# CONTROLSS_GLOBAL_CTRL_CONTROLSS_CTRL_502F0000h register map
Vendor: Texas Instruments
Peripheral module from a debugger description file (folder AM263P).
Registers are 32-bit, read-write, reset 0x0 unless marked. A register's access mark holds for its fields unless they carry their own. Offsets are as the file gives them; lines under a group give offsets from that group; [hi:lo] are bit positions; {n}, {i} and the like mark numbered series; 'fields as' and 'values as' point back to an identical list; <NAME> marks a mode.

## CONTROLSS_CTRL
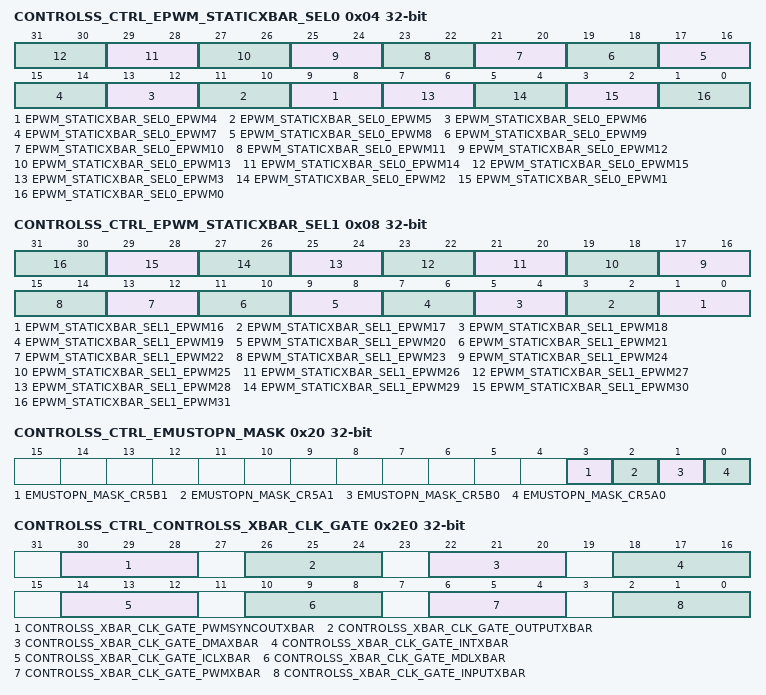
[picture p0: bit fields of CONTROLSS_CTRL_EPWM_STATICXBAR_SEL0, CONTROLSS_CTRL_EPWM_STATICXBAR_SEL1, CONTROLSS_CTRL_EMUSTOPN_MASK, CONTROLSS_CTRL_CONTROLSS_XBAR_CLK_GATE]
0x04 CONTROLSS_CTRL_EPWM_STATICXBAR_SEL0 — Static crossbar for epwm select.
  [2n+1:2n] EPWM_STATICXBAR_SEL0_EPWM{n} (n=4..15) — EPWM{n} access from PCR grouping. Write the following value to access groups - - 2'b00 = G0, 2'b01 =G1, 2'b10 =G2, 2'b11 =G3
  [7:6] EPWM_STATICXBAR_SEL0_EPWM3 — EPWM3 access from PCR grouping. Write the following value to access groups - 2'b00 = G0, 2'b01 =G1, 2'b10 =G2, 2'b11 =G3
  [5:4] EPWM_STATICXBAR_SEL0_EPWM2 — EPWM2 access from PCR grouping. Write the following value to access groups - - 2'b00 = G0, 2'b01 =G1, 2'b10 =G2, 2'b11 =G3
  [3:2] EPWM_STATICXBAR_SEL0_EPWM1 — EPWM1 access from PCR grouping. Write the following value to access groups - - 2'b00 = G0, 2'b01 =G1, 2'b10 =G2, 2'b11 =G3
  [1:0] EPWM_STATICXBAR_SEL0_EPWM0 — EPWM0 access from PCR grouping. Write the following value to access groups - - 2'b00 = G0, 2'b01 =G1, 2'b10 =G2, 2'b11 =G3
0x08 CONTROLSS_CTRL_EPWM_STATICXBAR_SEL1 — Static crossbar for epwm select.
  [2n-31:2n-32] EPWM_STATICXBAR_SEL1_EPWM{n} (n=16..31) — EPWM{n} access from PCR grouping. Write the following value to access groups - - 2'b00 = G0, 2'b01 =G1, 2'b10 =G2, 2'b11 =G3
0x10 CONTROLSS_CTRL_EPWM_CLKSYNC — Epwm clock sync.
  [31:0] EPWM_CLKSYNC_BIT — EPWM clock sync for each EPWM instance. Set the bit corresponding to the instance number to enable that EPWM instance. When set, all enabled EPWM module clocks are started with the first rising edge of TBCLK aligned.Refer to TRM for more details.Writing 1'b1 will allow to enable corresponding EPWM instanceWriting 1'b0 will disable corresponding EPWM instance.
0x18 CONTROLSS_CTRL_SDFM1_CLK0_SEL — Sdfm1 clock select.
  [0] SDFM1_CLK0_SEL_SEL — SDFM1 clock CK0 selectWrite 1'b0: source is SDFM1 CK0 from PinmuxWrite 1'b1: source is SDFM0 CK0 from Pinmux
0x20 CONTROLSS_CTRL_EMUSTOPN_MASK — Bit-mask for debug suspend cpu cores to EPWM.
  [3] EMUSTOPN_MASK_CR5B1 — Bit-mask for debug suspend cpu cores to EPWM1'b0 : R5FSS1_CORE1 enabled to control EMUSTOPn1'b1 : R5FSS1_CORE1 disabled to control EMUSTOPn
  [2] EMUSTOPN_MASK_CR5A1 — Bit-mask for debug suspend cpu cores to EPWM1'b0 : R5FSS1_CORE0 enabled to control EMUSTOPn1'b1 : R5FSS1_CORE0 disabled to control EMUSTOPn
  [1] EMUSTOPN_MASK_CR5B0 — Bit-mask for debug suspend cpu cores to EPWM1'b0 : R5FSS0_CORE1 enabled to control EMUSTOPn1'b1 : R5FSS0_CORE1 disabled to control EMUSTOPn
  [0] EMUSTOPN_MASK_CR5A0 — Bit-mask for debug suspend cpu cores to EPWM1'b0 : R5FSS0_CORE0 enabled to control EMUSTOPn1'b1 : R5FSS0_CORE0 disabled to control EMUSTOPn
0x28 CONTROLSS_CTRL_CLB_AQ_EN0 — clb_aq_en0.
  [31:0] CLB_AQ_EN0_ENABLE — Enable ICCS control to CLB_AQ signal of PWM[15:0]. Set Bitx to 1'b1 to enable it for PWMx. Here x varies from 0-15.
0x30 CONTROLSS_CTRL_CLB_AQ_EN1 — clb_aq_en1.
  [31:0] CLB_AQ_EN1_ENABLE — Enable ICCS control to CLB_AQ signal of PWM[31:16].Set Bitx to 1'b1 to enable it for PWMx. Here x varies from 16-31.
0x38 CONTROLSS_CTRL_CLB_DB_EN0 — clb_db_en0.
  [31:0] CLB_DB_EN0_ENABLE — Enable ICCS control to CLB_DB signal of PWM[15:0]. Set Bitx to 1'b1 to enable it for PWMx. Here x varies from 0-15.
0x40 CONTROLSS_CTRL_CLB_DB_EN1 — clb_db_en1.
  [31:0] CLB_DB_EN1_ENABLE — Enable ICCS control to CLB_DB signal of PWM[31:16].Set Bitx to 1'b1 to enable it for PWMx. Here x varies from 16-31.
0x44 CONTROLSS_CTRL_ADCSOCFRCGBSEL — ADC Global SoC Force select.
  [6:0] ADCSOCFRCGBSEL_ENABLE — ADCSOCFRCGBSEL has one bit for each ADCBIT FIELD Descriptionbitx ADCx Indicate if ADCx selected for global SW trigger 1'b0 : Not selected for Global SW Trigger 1'b1 : Selected for Global SW TriggerReset Reset type: SYSRSnNote: x represents 0-4
0x48 CONTROLSS_CTRL_ADCSOCFRCGB — ADC Global SOC Force.
  [15:0] ADCSOCFRCGB_TRIG — ADCSOCFRCGB has one bit for each SOC[Start of conversion]BIT FIELD Descriptionbitxx SOCxx Indicate if SOCxx selected for global SW trigger 1'b0 : Not selected for Global SW Trigger 1'b1 : Selected for Global SW Trigger Reset type: SYSRSnNote: xx represents 0-15
0x4C CONTROLSS_CTRL_ADC_EXTCH_DLY_SEL — Mux select to choose delay for adc_extchsel.
  [0] ADC_EXTCH_DLY_SEL_SEL — MUX select to choose delayWrite 1'b0: 3 cycle delay[default]Write 1'b1: 6 cycle delay
0x50 CONTROLSS_CTRL_XBAR_LOOPBACK_CTRL — Mux select to enable Loopback for corresponding outputXBAR.
  [15:0] XBAR_LOOPBACK_CTRL_ENABLE — Mux select to enable Loopback for corresponding outputXBAR signal to the inputXBARWrite 1'b0: Loopback disabled [default]Write 1'b1: Loopback enable**Note: Each Mux select bit corresponds to the corresponding XBAR_LOOPBACK_CTRL_MUX
0x60 CONTROLSS_CTRL_EPWM_SOCA_SEL — Select line to choose EPWM SOC A to EQEPx.SOCA and PWMBAR.
  [31:0] EPWM_SOCA_SEL_SEL — MUX select to choose EPWM SOC A to EQEPx.SOCA and PWMBAR.Each bit in SOC_A_SEL corresponds to each inputEPWM_SOCA_SEL_0:pwm_soca_0EPWM_SOCA_SEL_1:pwm_soca_1EPWM_SOCA_SEL_2:pwm_soca_2EPWM_SOCA_SEL_3:pwm_soca_3EPWM_SOCA_SEL_4:pwm_soca_4EPWM_SOCA_SEL_5:pwm_soca_5EPWM_SOCA_SEL_6:pwm_soca_6EPWM_SOCA_SEL_7:pwm_soca_7EPWM_SOCA_SEL_8:pwm_soca_8EPWM_SOCA_SEL_9:pwm_soca_9EPWM_SOCA_SEL_10:pwm_soca_10EPWM_SOCA_SEL_11:pwm_soca_11EPWM_SOCA_SEL_12:pwm_soca_12EPWM_SOCA_SEL_13:pwm_soca_13EPWM_SOCA_SEL_14:pwm_soca_14EPWM_SOCA_SEL_15:pwm_soca_15EPWM_SOCA_SEL_16:pwm_soca_16EPWM_SOCA_SEL_17:pwm_soca_17EPWM_SOCA_SEL_18:pwm_soca_18EPWM_SOCA_SEL_19:pwm_soca_19EPWM_SOCA_SEL_20:pwm_soca_20EPWM_SOCA_SEL_21:pwm_soca_21EPWM_SOCA_SEL_22:pwm_soca_22EPWM_SOCA_SEL_23:pwm_soca_23EPWM_SOCA_SEL_24:pwm_soca_24EPWM_SOCA_SEL_25:pwm_soca_25EPWM_SOCA_SEL_26:pwm_soca_26EPWM_SOCA_SEL_27:pwm_soca_27EPWM_SOCA_SEL_28:pwm_soca_28EPWM_SOCA_SEL_29:pwm_soca_29EPWM_SOCA_SEL_30:pwm_soca_30EPWM_SOCA_SEL_31:pwm_soca_31
0x64 CONTROLSS_CTRL_EPWM_SOCB_SEL — Select line to choose EPWM SOC B to EQEPx.SOCB and PWMBAR.
  [31:0] EPWM_SOCB_SEL_SEL — MUX select to choose EPWM SOC B to EQEPx.SOCB and PWMBAR.Each bit in SOC_B_SEL corresponds to each inputEPWM_SOCB_SEL_0:pwm_socb_0EPWM_SOCB_SEL_1:pwm_socb_1EPWM_SOCB_SEL_2:pwm_socb_2EPWM_SOCB_SEL_3:pwm_socb_3EPWM_SOCB_SEL_4:pwm_socb_4EPWM_SOCB_SEL_5:pwm_socb_5EPWM_SOCB_SEL_6:pwm_socb_6EPWM_SOCB_SEL_7:pwm_socb_7EPWM_SOCB_SEL_8:pwm_socb_8EPWM_SOCB_SEL_9:pwm_socb_9EPWM_SOCB_SEL_10:pwm_socb_10EPWM_SOCB_SEL_11:pwm_socb_11EPWM_SOCB_SEL_12:pwm_socb_12EPWM_SOCB_SEL_13:pwm_socb_13EPWM_SOCB_SEL_14:pwm_socb_14EPWM_SOCB_SEL_15:pwm_socb_15EPWM_SOCB_SEL_16:pwm_socb_16EPWM_SOCB_SEL_17:pwm_socb_17EPWM_SOCB_SEL_18:pwm_socb_18EPWM_SOCB_SEL_19:pwm_socb_19EPWM_SOCB_SEL_20:pwm_socb_20EPWM_SOCB_SEL_21:pwm_socb_21EPWM_SOCB_SEL_22:pwm_socb_22EPWM_SOCB_SEL_23:pwm_socb_23EPWM_SOCB_SEL_24:pwm_socb_24EPWM_SOCB_SEL_25:pwm_socb_25EPWM_SOCB_SEL_26:pwm_socb_26EPWM_SOCB_SEL_27:pwm_socb_27EPWM_SOCB_SEL_28:pwm_socb_28EPWM_SOCB_SEL_29:pwm_socb_29EPWM_SOCB_SEL_30:pwm_socb_30EPWM_SOCB_SEL_31:pwm_socb_31
{0x70+4i} CONTROLSS_CTRL_ADCEXTCHXBAR{i}_G0_SEL (i=0..9) — ADC EXTCH XBAR [x] Input Select.
  [3:0] ADCEXTCHXBAR{i}_G0_SEL_SEL — ADC EXTCH XBAR 0 Input Select4'b0000: ADC0EXTCHSEL_BIT04'b0001: ADC0EXTCHSEL_BIT14'b0010: ADC1EXTCHSEL_BIT04'b0011: ADC1EXTCHSEL_BIT14'b0100: ADC2EXTCHSEL_BIT04'b0101: ADC2EXTCHSEL_BIT14'b0110: ADC3EXTCHSEL_BIT04'b0111: ADC3EXTCHSEL_BIT14'b1000: ADC4EXTCHSEL_BIT04'b1001: ADC4EXTCHSEL_BIT14'b1010: ADC_R0_EXTCHSEL_BIT04'b1011: ADC_R0_EXTCHSEL_BIT14'b1100: ADC_R1_EXTCHSEL_BIT04'b1101: ADC_R1_EXTCHSEL_BIT1Example: ADC2EXTCHSEL_BIT0 needs to be connect to ADC_EXTCH_XBAROUT3, then ADCEXTCHXBAR3.G0.SEL set to 4'b0100
{0xB0+4i} CONTROLSS_CTRL_SDFM0_CLK{i}_OUT_SEL (i=0..3) — SDFM0_CLK[x]_OUT Input Select.
  [0] SDFM0_CLK{i}_OUT_SEL_SEL — SDFM0_CLK{i}_OUT Input selectWrite 1'b0: ECAP{i+4}_OUT [default]Write 1'b1: ECAP{i+12}_OUT
0xC0 CONTROLSS_CTRL_SDFM1_CLK0_OUT_SEL — SDFM1_CLK[x]_OUT Input Select.
  [0] SDFM1_CLK0_OUT_SEL_SEL — SDFM1_CLK0_OUT Input selectWrite 1'b0: ECAP7_OUT [default]Write 1'b1: ECAP15_OUT
0xC4 CONTROLSS_CTRL_SDFM1_CLK1_OUT_SEL — SDFM1_CLK[x]_OUT Input Select.
  [0] SDFM1_CLK1_OUT_SEL_SEL — SDFM1_CLK1_OUT Input selectWrite 1'b0: ECAP6_OUT [default]Write 1'b1: ECAP14_OUT
0xC8 CONTROLSS_CTRL_SDFM1_CLK2_OUT_SEL — SDFM1_CLK[x]_OUT Input Select.
  [0] SDFM1_CLK2_OUT_SEL_SEL — SDFM1_CLK2_OUT Input selectWrite 1'b0: ECAP5_OUT [default]Write 1'b1: ECAP13_OUT
0xCC CONTROLSS_CTRL_SDFM1_CLK3_OUT_SEL — SDFM1_CLK[x]_OUT Input Select.
  [0] SDFM1_CLK3_OUT_SEL_SEL — SDFM1_CLK3_OUT Input selectWrite 1'b0: ECAP4_OUT [default]Write 1'b1: ECAP12_OUT
{0xE0+4i} CONTROLSS_CTRL_CONTROLSS_G{i}_EPWM_WLINK (i=0..3) — Enable for WLINK of EPWM groups.
  [31:0] CONTROLSS_G{i}_EPWM_WLINK_ENABLE — Writing 1'b1 to the bit enables the corresponding EPWM instance for WLINK feature
{0x100+4i} CONTROLSS_CTRL_EPWM{i}_CLK_GATE (i=0..31) — To clock gate epwm[x].
  [2:0] EPWM{i}_CLK_GATE_CLK_GATE — Writing 3'b111 will gate clock for corresponding epwm
{0x180+4i} CONTROLSS_CTRL_FSI_TX{i}_CLK_GATE (i=0..3) — fsi_tx[x] clock gate.
  [2:0] FSI_TX{i}_CLK_GATE_CLK_GATE — Writing 3'b111 will gate clock for corresponding fsi_tx
{0x190+4i} CONTROLSS_CTRL_FSI_RX{i}_CLK_GATE (i=0..3) — fsi_rx[x] clock gate.
  [2:0] FSI_RX{i}_CLK_GATE_CLK_GATE — Writing 3'b111 will gate clock for corresponding fsi_rx
{0x1A0+4i} CONTROLSS_CTRL_CMPSSA{i}_CLK_GATE (i=0..9) — cmpssa[x] clock gate.
  [2:0] CMPSSA{i}_CLK_GATE_CLK_GATE — Writing 3'b111 will gate clock for corresponding cmpssa
{0x1D0+4i} CONTROLSS_CTRL_CMPSSB{i}_CLK_GATE (i=0..9) — cmpssb[x] clock gate.
  [2:0] CMPSSB{i}_CLK_GATE_CLK_GATE — Writing 3'b111 will gate clock for corresponding cmpssb
{0x200+4i} CONTROLSS_CTRL_ECAP{i}_CLK_GATE (i=0..15) — Ecap[x] clock gate.
  [2:0] ECAP{i}_CLK_GATE_CLK_GATE — Writing 3'b111 will gate clock for corresponding ecap
{0x240+4i} CONTROLSS_CTRL_EQEP{i}_CLK_GATE (i=0..2) — Eqep[x] clock gate.
  [2:0] EQEP{i}_CLK_GATE_CLK_GATE — Writing 3'b111 will gate clock for corresponding eqep
0x250 CONTROLSS_CTRL_SDFM0_CLK_GATE — Sdfm[x] clock gate.
  [2:0] SDFM0_CLK_GATE_CLK_GATE — Writing 3'b111 will gate clock for corresponding sdfm
0x254 CONTROLSS_CTRL_SDFM1_CLK_GATE — Sdfm[x] clock gate.
  [2:0] SDFM1_CLK_GATE_CLK_GATE — Writing 3'b111 will gate clock for corresponding sdfm
0x258 CONTROLSS_CTRL_DAC_CLK_GATE — dac clock gate.
  [2:0] DAC_CLK_GATE_CLK_GATE — Writing 3'b111 will gate clock for dac
{0x25C+4i} CONTROLSS_CTRL_ADC{i}_CLK_GATE (i=0..4) — Adc[x] clock gate.
  [2:0] ADC{i}_CLK_GATE_CLK_GATE — Writing 3'b111 will gate clock for corresponding adc
{0x270+4i} CONTROLSS_CTRL_OTTO{i}_CLK_GATE (i=0..3) — Otto[x] clock gate.
  [2:0] OTTO{i}_CLK_GATE_CLK_GATE — Writing 3'b111 will gate clock for corresponding otto
0x280 CONTROLSS_CTRL_SDFM0_PLL_CLK_GATE — Sdfm[x]_pll clock gate.
  [2:0] SDFM0_PLL_CLK_GATE_CLK_GATE — Writing 3'b111 will gate clock for corresponding sdfm pll clock
0x284 CONTROLSS_CTRL_SDFM1_PLL_CLK_GATE — Sdfm[x]_pll clock gate.
  [2:0] SDFM1_PLL_CLK_GATE_CLK_GATE — Writing 3'b111 will gate clock for corresponding sdfm pll clock
{0x288+4i} CONTROLSS_CTRL_FSI_TX{i}_PLL_CLK_GATE (i=0..3) — fsi_tx[x]_pll clock gate.
  [2:0] FSI_TX{i}_PLL_CLK_GATE_CLK_GATE — Writing 3'b111 will gate clock for corresponding fsi rx pll clock
0x298 CONTROLSS_CTRL_HW_RESOLVER_CLK_GATE — Hardware resolver clock gate.
  [2:0] HW_RESOLVER_CLK_GATE_CLK_GATE — Writing 3'b111 will gate clock for corresponding hw_resolver
{0x29C+4i} CONTROLSS_CTRL_ADC_SCTILE{i}_CLK_GATE (i=0..11) — ADC Safecheck tiles clock gate.
  [2:0] ADC_SCTILE{i}_CLK_GATE_CLK_GATE — Writing 3'b111 will gate clock for corresponding adc safety tiles
0x2DC CONTROLSS_CTRL_ADC_AGG0_CLK_GATE — ADC Aggregator clock gate.
  [2:0] ADC_AGG0_CLK_GATE_CLK_GATE — Writing 3'b111 will gate clock for corresponding adc aggregator
0x2E0 CONTROLSS_CTRL_CONTROLSS_XBAR_CLK_GATE — clock gate for eight XBARs.
  [30:28] CONTROLSS_XBAR_CLK_GATE_PWMSYNCOUTXBAR — Writing 3'b111 to register will clock gate the corresponding XBAR
  [26:24] CONTROLSS_XBAR_CLK_GATE_OUTPUTXBAR — Writing 3'b111 to register will clock gate the corresponding XBAR
  [22:20] CONTROLSS_XBAR_CLK_GATE_DMAXBAR — Writing 3'b111 to register will clock gate the corresponding XBAR
  [18:16] CONTROLSS_XBAR_CLK_GATE_INTXBAR — Writing 3'b111 to register will clock gate the corresponding XBAR
  [14:12] CONTROLSS_XBAR_CLK_GATE_ICLXBAR — Writing 3'b111 to register will clock gate the corresponding XBAR
  [10:8] CONTROLSS_XBAR_CLK_GATE_MDLXBAR — Writing 3'b111 to register will clock gate the corresponding XBAR
  [6:4] CONTROLSS_XBAR_CLK_GATE_PWMXBAR — Writing 3'b111 to register will clock gate the corresponding XBAR
  [2:0] CONTROLSS_XBAR_CLK_GATE_INPUTXBAR — Writing 3'b111 to register will clock gate the corresponding XBAR
0x2E4 CONTROLSS_CTRL_ADCR0_CLK_GATE — Adcr[x] clock gate.
  [2:0] ADCR0_CLK_GATE_CLK_GATE — Writing 3'b111 will gate clock for corresponding adc
0x2E8 CONTROLSS_CTRL_ADCR1_CLK_GATE — Adcr[x] clock gate.
  [2:0] ADCR1_CLK_GATE_CLK_GATE — Writing 3'b111 will gate clock for corresponding adc
{0x300+4i} CONTROLSS_CTRL_EPWM{i}_RST (i=0..31) — Epwm[x]_reset.
  [2:0] EPWM{i}_RST_RST — Writing 3'b111 will generate reset for corresponding epwm
{0x380+4i} CONTROLSS_CTRL_FSI_TX{i}_RST (i=0..3) — fsi_tx[x]_reset.
  [2:0] FSI_TX{i}_RST_RST — Writing 3'b111 will generate reset for corresponding fsi_tx
{0x390+4i} CONTROLSS_CTRL_FSI_RX{i}_RST (i=0..3) — fsi_rx[x]_reset.
  [2:0] FSI_RX{i}_RST_RST — Writing 3'b111 will generate reset for corresponding fsi_rx
{0x3A0+4i} CONTROLSS_CTRL_CMPSSA{i}_RST (i=0..9) — cmpssa[x]_reset.
  [2:0] CMPSSA{i}_RST_RST — Writing 3'b111 will generate reset for corresponding cmpssa
{0x3D0+4i} CONTROLSS_CTRL_CMPSSB{i}_RST (i=0..9) — cmpssb[x]_reset.
  [2:0] CMPSSB{i}_RST_RST — Writing 3'b111 will generate reset for corresponding cmpssb
{0x400+4i} CONTROLSS_CTRL_ECAP{i}_RST (i=0..15) — Ecap[x]_reset.
  [2:0] ECAP{i}_RST_RST — Writing 3'b111 will generate reset for corresponding ecap
{0x440+4i} CONTROLSS_CTRL_EQEP{i}_RST (i=0..2) — Eqep[x]_reset.
  [2:0] EQEP{i}_RST_RST — Writing 3'b111 will generate reset for corresponding eqep
0x450 CONTROLSS_CTRL_SDFM0_RST — Sdfm[x]_reset.
  [2:0] SDFM0_RST_RST — Writing 3'b111 will generate reset for corresponding sdfm
0x454 CONTROLSS_CTRL_SDFM1_RST — Sdfm[x]_reset.
  [2:0] SDFM1_RST_RST — Writing 3'b111 will generate reset for corresponding sdfm
0x458 CONTROLSS_CTRL_DAC_RST — dac_reset.
  [2:0] DAC_RST_RST — Writing 3'b111 will generate reset for dac
{0x45C+4i} CONTROLSS_CTRL_ADC{i}_RST (i=0..4) — Adc[x]_reset.
  [2:0] ADC{i}_RST_RST — Writing 3'b111 will generate reset for corresponding adc
{0x470+4i} CONTROLSS_CTRL_OTTO{i}_RST (i=0..3) — Otto[x]_reset.
  [2:0] OTTO{i}_RST_RST — Writing 3'b111 will generate reset for corresponding otto
0x480 CONTROLSS_CTRL_HW_RESOLVER_RST — Hardware resolver reset.
  [2:0] HW_RESOLVER_RST_RST — Writing 3'b111 will generate reset for corresponding hw_resolver
{0x484+4i} CONTROLSS_CTRL_ADC_SCTILE{i}_RST (i=0..11) — ADC Safecheck tiles Reset.
  [2:0] ADC_SCTILE{i}_RST_RST — Writing 3'b111 will generate reset for corresponding adc safety tiles
0x4C4 CONTROLSS_CTRL_ADC_AGG0_RST — ADC Aggregator Reset.
  [2:0] ADC_AGG0_RST_RST — Writing 3'b111 will generate reset for corresponding adc aggregator
0x4C8 CONTROLSS_CTRL_ADCR0_RST — Adcr[x] reset.
  [2:0] ADCR0_RST_RST — Writing 3'b111 will generate reset for corresponding adc
0x4CC CONTROLSS_CTRL_ADCR1_RST — Adcr[x] reset.
  [2:0] ADCR1_RST_RST — Writing 3'b111 will generate reset for corresponding adc
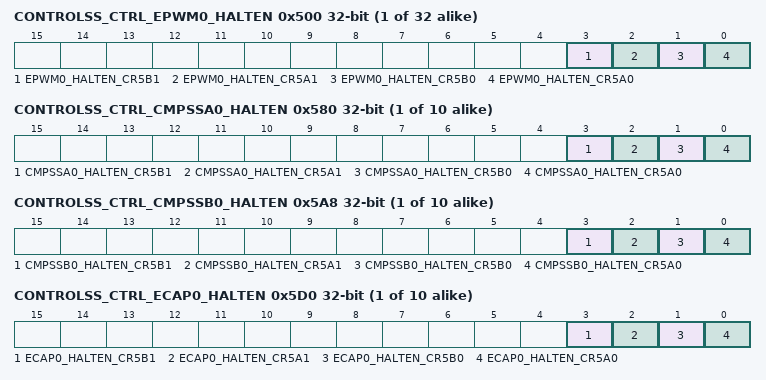
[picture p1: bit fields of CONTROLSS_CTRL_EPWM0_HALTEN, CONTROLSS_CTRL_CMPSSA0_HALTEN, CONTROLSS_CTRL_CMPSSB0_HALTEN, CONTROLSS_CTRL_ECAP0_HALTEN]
{0x500+4i} CONTROLSS_CTRL_EPWM{i}_HALTEN (i=0..31) — Epwm halt enable.
  [3] EPWM{i}_HALTEN_CR5B1 — Write 1'b0: IP Halt disabled with corresponding CPU haltWrite 1'b1: IP Halt enabled with corresponding CPU halt
  [2] EPWM{i}_HALTEN_CR5A1 — Write 1'b0: IP Halt disabled with corresponding CPU haltWrite 1'b1: IP Halt enabled with corresponding CPU halt
  [1] EPWM{i}_HALTEN_CR5B0 — Write 1'b0: IP Halt disabled with corresponding CPU haltWrite 1'b1: IP Halt enabled with corresponding CPU halt
  [0] EPWM{i}_HALTEN_CR5A0 — Write 1'b0: IP Halt disabled with corresponding CPU haltWrite 1'b1: IP Halt enabled with corresponding CPU halt
{0x580+4i} CONTROLSS_CTRL_CMPSSA{i}_HALTEN (i=0..9) — cmpssa halt enable.
  [3] CMPSSA{i}_HALTEN_CR5B1 — Write 1'b0: IP Halt disabled with corresponding CPU haltWrite 1'b1: IP Halt enabled with corresponding CPU halt
  [2] CMPSSA{i}_HALTEN_CR5A1 — Write 1'b0: IP Halt disabled with corresponding CPU haltWrite 1'b1: IP Halt enabled with corresponding CPU halt
  [1] CMPSSA{i}_HALTEN_CR5B0 — Write 1'b0: IP Halt disabled with corresponding CPU haltWrite 1'b1: IP Halt enabled with corresponding CPU halt
  [0] CMPSSA{i}_HALTEN_CR5A0 — Write 1'b0: IP Halt disabled with corresponding CPU haltWrite 1'b1: IP Halt enabled with corresponding CPU halt
{0x5A8+4i} CONTROLSS_CTRL_CMPSSB{i}_HALTEN (i=0..9) — cmpssb halt enable.
  [3] CMPSSB{i}_HALTEN_CR5B1 — Write 1'b0: IP Halt disabled with corresponding CPU haltWrite 1'b1: IP Halt enabled with corresponding CPU halt
  [2] CMPSSB{i}_HALTEN_CR5A1 — Write 1'b0: IP Halt disabled with corresponding CPU haltWrite 1'b1: IP Halt enabled with corresponding CPU halt
  [1] CMPSSB{i}_HALTEN_CR5B0 — Write 1'b0: IP Halt disabled with corresponding CPU haltWrite 1'b1: IP Halt enabled with corresponding CPU halt
  [0] CMPSSB{i}_HALTEN_CR5A0 — Write 1'b0: IP Halt disabled with corresponding CPU haltWrite 1'b1: IP Halt enabled with corresponding CPU halt
{0x5D0+4i} CONTROLSS_CTRL_ECAP{i}_HALTEN (i=0..9) — Ecap halt enable.
  [3] ECAP{i}_HALTEN_CR5B1 — Write 1'b0: IP Halt disabled with corresponding CPU haltWrite 1'b1: IP Halt enabled with corresponding CPU halt
  [2] ECAP{i}_HALTEN_CR5A1 — Write 1'b0: IP Halt disabled with corresponding CPU haltWrite 1'b1: IP Halt enabled with corresponding CPU halt
  [1] ECAP{i}_HALTEN_CR5B0 — Write 1'b0: IP Halt disabled with corresponding CPU haltWrite 1'b1: IP Halt enabled with corresponding CPU halt
  [0] ECAP{i}_HALTEN_CR5A0 — Write 1'b0: IP Halt disabled with corresponding CPU haltWrite 1'b1: IP Halt enabled with corresponding CPU halt
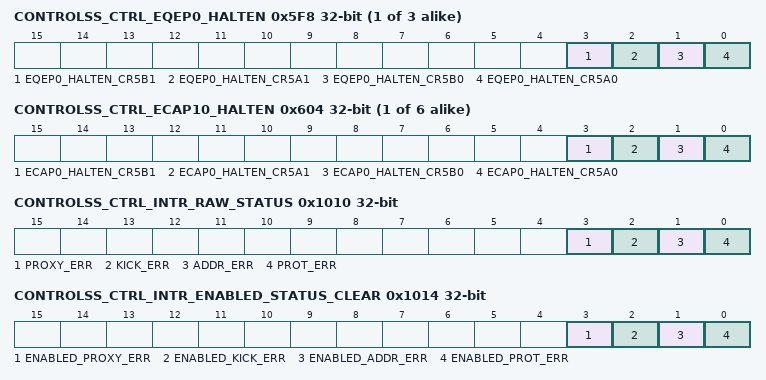
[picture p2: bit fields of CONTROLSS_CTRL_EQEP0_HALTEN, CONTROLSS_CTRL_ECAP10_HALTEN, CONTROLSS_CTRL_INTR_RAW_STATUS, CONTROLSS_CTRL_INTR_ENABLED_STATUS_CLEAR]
{0x5F8+4i} CONTROLSS_CTRL_EQEP{i}_HALTEN (i=0..2) — Eqep halt enable.
  [3] EQEP{i}_HALTEN_CR5B1 — Write 1'b0: IP Halt disabled with corresponding CPU haltWrite 1'b1: IP Halt enabled with corresponding CPU halt
  [2] EQEP{i}_HALTEN_CR5A1 — Write 1'b0: IP Halt disabled with corresponding CPU haltWrite 1'b1: IP Halt enabled with corresponding CPU halt
  [1] EQEP{i}_HALTEN_CR5B0 — Write 1'b0: IP Halt disabled with corresponding CPU haltWrite 1'b1: IP Halt enabled with corresponding CPU halt
  [0] EQEP{i}_HALTEN_CR5A0 — Write 1'b0: IP Halt disabled with corresponding CPU haltWrite 1'b1: IP Halt enabled with corresponding CPU halt
{0x5DC+4i} CONTROLSS_CTRL_ECAP{i}_HALTEN (i=10..15) — Ecap halt enable.
  fields as CONTROLSS_CTRL_ECAP0_HALTEN
0x1008 CONTROLSS_CTRL_LOCK0_KICK0 — - KICK0 component.
  [31:0] LOCK0_KICK0 — - KICK0 component
0x100C CONTROLSS_CTRL_LOCK0_KICK1 — - KICK1 component.
  [31:0] LOCK0_KICK1 — - KICK1 component
0x1010 CONTROLSS_CTRL_INTR_RAW_STATUS access not given — Interrupt Raw Status/Set Register.
  [3] PROXY_ERR — Proxy0 access violation error. Raw status is read. Write a 1 to set the status. Writing a 0 has no effect. (access R/W1TS)
  [2] KICK_ERR — Kick access violation error. Raw status is read. Write a 1 to set the status. Writing a 0 has no effect. (access R/W1TS)
  [1] ADDR_ERR — Addressing violation error. Raw status is read. Write a 1 to set the status. Writing a 0 has no effect. (access R/W1TS)
  [0] PROT_ERR — Protection violation error. Raw status is read. Write a 1 to set the status. Writing a 0 has no effect. (access R/W1TS)
0x1014 CONTROLSS_CTRL_INTR_ENABLED_STATUS_CLEAR access not given — Interrupt Enabled Status/Clear register.
  [3] ENABLED_PROXY_ERR — Proxy0 access violation error. Enabled status is read. Write a 1 to clear the status. Writing a 0 has no effect. (access R/W1TC)
  [2] ENABLED_KICK_ERR — Kick access violation error. Enabled status is read. Write a 1 to clear the status. Writing a 0 has no effect. (access R/W1TC)
  [1] ENABLED_ADDR_ERR — Addressing violation error. Enabled status is read. Write a 1 to clear the status. Writing a 0 has no effect. (access R/W1TC)
  [0] ENABLED_PROT_ERR — Protection violation error. Enabled status is read. Write a 1 to clear the status. Writing a 0 has no effect. (access R/W1TC)
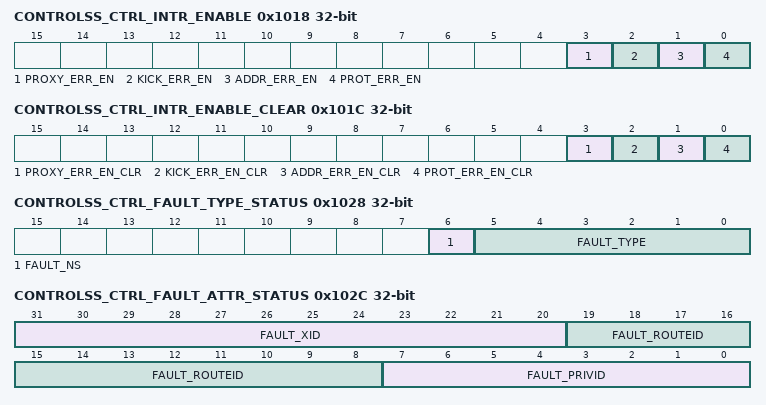
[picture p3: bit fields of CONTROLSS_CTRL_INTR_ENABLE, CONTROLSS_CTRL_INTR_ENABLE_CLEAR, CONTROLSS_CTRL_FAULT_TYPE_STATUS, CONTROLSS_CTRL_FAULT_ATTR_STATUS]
0x1018 CONTROLSS_CTRL_INTR_ENABLE access not given — Interrupt Enable register.
  [3] PROXY_ERR_EN — Proxy0 access violation error enable. Write a 1 to set the enable. Writing a 0 has no effect. (access R/W1TS)
  [2] KICK_ERR_EN — Kick access violation error enable. Write a 1 to set the enable. Writing a 0 has no effect. (access R/W1TS)
  [1] ADDR_ERR_EN — Addressing violation error enable. Write a 1 to set the enable. Writing a 0 has no effect. (access R/W1TS)
  [0] PROT_ERR_EN — Protection violation error enable. Write a 1 to set the enable. Writing a 0 has no effect. (access R/W1TS)
0x101C CONTROLSS_CTRL_INTR_ENABLE_CLEAR access not given — Interrupt Enable Clear register.
  [3] PROXY_ERR_EN_CLR — Proxy0 access violation error enable clear. Write a 1 to clear the enable. Writing a 0 has no effect. (access R/W1TC)
  [2] KICK_ERR_EN_CLR — Kick access violation error enable clear. Write a 1 to clear the enable. Writing a 0 has no effect. (access R/W1TC)
  [1] ADDR_ERR_EN_CLR — Addressing violation error enable clear. Write a 1 to clear the enable. Writing a 0 has no effect. (access R/W1TC)
  [0] PROT_ERR_EN_CLR — Protection violation error enable clear. Write a 1 to clear the enable. Writing a 0 has no effect. (access R/W1TC)
0x1020 CONTROLSS_CTRL_EOI — EOI register.
  [7:0] EOI_VECTOR — EOI vector value. Write this with interrupt distribution value in the chip.
0x1024 CONTROLSS_CTRL_FAULT_ADDRESS ro — Fault Address register.
  [31:0] FAULT_ADDR — Fault Address.
0x1028 CONTROLSS_CTRL_FAULT_TYPE_STATUS ro — Fault Type Status register.
  [6] FAULT_NS — Non-secure access.
  [5:0] FAULT_TYPE — Fault Type 10_0000 = Supervisor read fault - priv = 1 dir = 1 dtype != 1 01_0000 = Supervisor write fault - priv = 1 dir = 0 00_1000 = Supervisor execute fault - priv = 1 dir = 1 dtype = 1 00_0100 = User read fault - priv = 0 dir = 1 dtype = 1 00_0010 = User write fault - priv = 0 dir = 0 00_0001 = User execute fault - priv = 0 dir = 1 dtype = 1 00_0000 = No fault
0x102C CONTROLSS_CTRL_FAULT_ATTR_STATUS ro — Fault Attribute Status register.
  [31:20] FAULT_XID — XID.
  [19:8] FAULT_ROUTEID — Route ID.
  [7:0] FAULT_PRIVID — Privilege ID.
0x1030 CONTROLSS_CTRL_FAULT_CLEAR wo — Fault Clear register.
  [0] FAULT_CLR — Fault clear. Writing a 1 clears the current fault. Writing a 0 has no effect.
